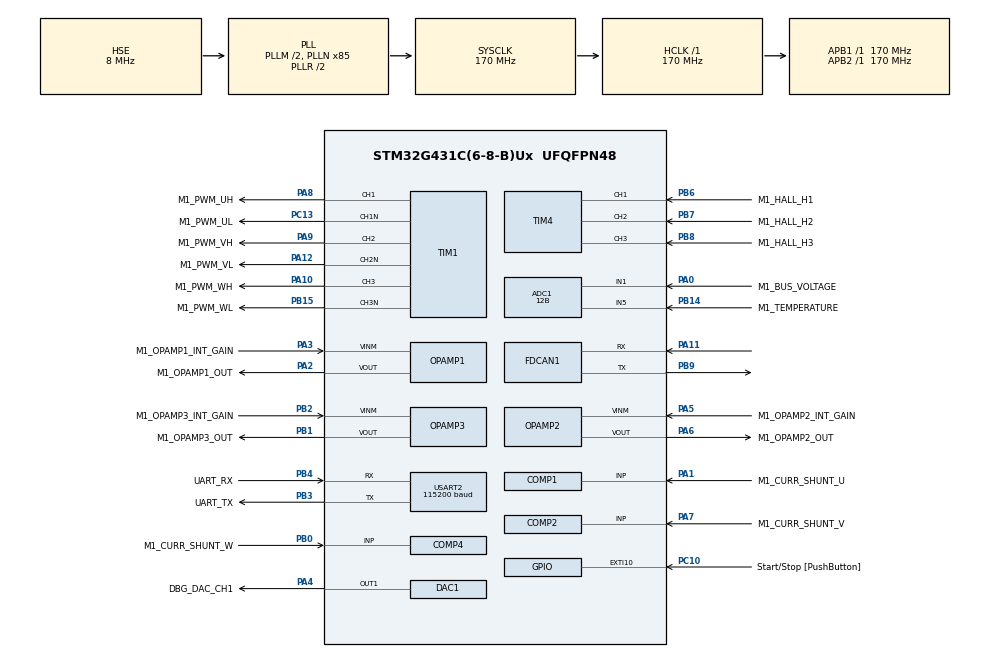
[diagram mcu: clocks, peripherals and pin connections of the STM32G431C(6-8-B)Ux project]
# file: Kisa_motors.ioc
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ADC1.Channel-1\#ChannelRegularConversion=ADC_CHANNEL_1
ADC1.Channel-2\#ChannelRegularConversion=ADC_CHANNEL_5
ADC1.ClockPrescaler=ADC_CLOCK_ASYNC_DIV4
ADC1.ContinuousConvMode=DISABLE
ADC1.DMAContinuousRequests=DISABLE
ADC1.DataAlign=ADC_DATAALIGN_LEFT
ADC1.DiscontinuousConvMode=DISABLE
ADC1.EOCSelection=ADC_EOC_SINGLE_CONV
ADC1.EnableAnalogWatchDog1=false
ADC1.EnableAnalogWatchDog2=false
ADC1.EnableAnalogWatchDog3=false
ADC1.EnableInjectedConversion=ENABLE
ADC1.EnableRegularConversion=ENABLE
ADC1.ExternalTrigConv=ADC_SOFTWARE_START
ADC1.ExternalTrigConvEdge=ADC_EXTERNALTRIGCONVEDGE_NONE
ADC1.ExternalTrigInjecConv=ADC_EXTERNALTRIGINJEC_T1_CC4
ADC1.ExternalTrigInjecConvEdge=ADC_EXTERNALTRIGINJECCONV_EDGE_RISING
ADC1.InjNumberOfConversion=2
ADC1.InjectedChannel-1\#ChannelInjectedConversion=ADC_CHANNEL_3
ADC1.InjectedChannel-2\#ChannelInjectedConversion=ADC_CHANNEL_12
ADC1.InjectedConvMode=None
ADC1.InjectedOffset-1\#ChannelInjectedConversion=0
ADC1.InjectedOffset-2\#ChannelInjectedConversion=0
ADC1.InjectedOffsetNumber-1\#ChannelInjectedConversion=ADC_OFFSET_NONE
ADC1.InjectedOffsetNumber-2\#ChannelInjectedConversion=ADC_OFFSET_NONE
ADC1.InjectedRank-1\#ChannelInjectedConversion=1
ADC1.InjectedRank-2\#ChannelInjectedConversion=2
ADC1.InjectedSamplingTime-1\#ChannelInjectedConversion=ADC_SAMPLETIME_6CYCLES_5
ADC1.InjectedSamplingTime-2\#ChannelInjectedConversion=ADC_SAMPLETIME_6CYCLES_5
ADC1.LowPowerAutoWait=DISABLE
ADC1.NbrOfConversion=2
ADC1.NbrOfConversionFlag=1
ADC1.Offset-1\#ChannelRegularConversion=0
ADC1.Offset-2\#ChannelRegularConversion=0
ADC1.OffsetNumber-1\#ChannelRegularConversion=ADC_OFFSET_NONE
ADC1.OffsetNumber-2\#ChannelRegularConversion=ADC_OFFSET_NONE
ADC1.Overrun=ADC_OVR_DATA_PRESERVED
ADC1.Rank-1\#ChannelRegularConversion=1
ADC1.Rank-2\#ChannelRegularConversion=2
ADC1.Resolution=ADC_RESOLUTION_12B
ADC1.SamplingTime-1\#ChannelRegularConversion=ADC_SAMPLETIME_47CYCLES_5
ADC1.SamplingTime-2\#ChannelRegularConversion=ADC_SAMPLETIME_47CYCLES_5
ADC1.ScanConvMode=ADC_SCAN_ENABLE
ADC1.master=1
ADC2.ClockPrescaler=ADC_CLOCK_ASYNC_DIV4
ADC2.ContinuousConvMode=DISABLE
ADC2.DMAContinuousRequests=DISABLE
ADC2.DataAlign=ADC_DATAALIGN_LEFT
ADC2.DiscontinuousConvMode=DISABLE
ADC2.EOCSelection=ADC_EOC_SINGLE_CONV
ADC2.EnableAnalogWatchDog1=false
ADC2.EnableAnalogWatchDog2=false
ADC2.EnableAnalogWatchDog3=false
ADC2.EnableInjectedConversion=ENABLE
ADC2.EnableRegularConversion=DISABLE
ADC2.ExternalTrigInjecConv=ADC_EXTERNALTRIGINJEC_T1_CC4
ADC2.ExternalTrigInjecConvEdge=ADC_EXTERNALTRIGINJECCONV_EDGE_RISING
ADC2.InjNumberOfConversion=2
ADC2.InjectedChannel-1\#ChannelInjectedConversion=ADC_CHANNEL_3
ADC2.InjectedChannel-2\#ChannelInjectedConversion=ADC_CHANNEL_VOPAMP3_ADC2
ADC2.InjectedConvMode=None
ADC2.InjectedOffset-1\#ChannelInjectedConversion=0
ADC2.InjectedOffset-2\#ChannelInjectedConversion=0
ADC2.InjectedOffsetNumber-1\#ChannelInjectedConversion=ADC_OFFSET_NONE
ADC2.InjectedOffsetNumber-2\#ChannelInjectedConversion=ADC_OFFSET_NONE
ADC2.InjectedRank-1\#ChannelInjectedConversion=1
ADC2.InjectedRank-2\#ChannelInjectedConversion=2
ADC2.InjectedSamplingTime-1\#ChannelInjectedConversion=ADC_SAMPLETIME_6CYCLES_5
ADC2.InjectedSamplingTime-2\#ChannelInjectedConversion=ADC_SAMPLETIME_6CYCLES_5
ADC2.LowPowerAutoWait=DISABLE
ADC2.Overrun=ADC_OVR_DATA_PRESERVED
ADC2.Resolution=ADC_RESOLUTION_12B
ADC2.ScanConvMode=ADC_SCAN_ENABLE
ADC2.master=1
COMP1.Output=COMP_OUTPUT_TIM1BKIN2
COMP2.Output=COMP_OUTPUT_TIM1BKIN2
COMP4.Output=COMP_OUTPUT_TIM1BKIN2
DAC1.DAC_OutputBuffer=DAC_OUTPUTBUFFER_DISABLE
DAC1.DAC_Trigger_OUT1=DAC_TRIGGER_SOFTWARE
ExtraMW=MotorControl
ExtraMW.MotorControl.Config=MotorControl
ExtraMW.MotorControl.Mode=MotorControl
ExtraMW.MotorControl.Root=MCSDK_v5.4.4/MotorControl
ExtraMW.MotorControl.Template=templates
FDCAN1.ClockDivider=FDCAN_CLOCK_DIV10
FDCAN1.DataTimeSeg1=4
FDCAN1.DataTimeSeg2=4
FDCAN1.NominalPrescaler=17
FDCAN1.NominalTimeSeg1=4
FDCAN1.NominalTimeSeg2=4
Mcu.Family=STM32G4
Mcu.Name=STM32G431C(6-8-B)Ux
Mcu.Package=UFQFPN48
MotorControl.ADC_1_PERIPH=ADC1
MotorControl.ADC_2_PERIPH=ADC2
MotorControl.ADC_AHBPERIPH=RCC_AHBPeriph_ADC12
MotorControl.ADC_CLOCK_WB_DIV=4
MotorControl.ADC_CLOCK_WB_FREQ=68
MotorControl.ADC_PERIPH=ADC1
MotorControl.ADC_REFERENCE_VOLTAGE=3.30
MotorControl.ALIGNMENT_ANGLE_DEG=90
MotorControl.ALIGNMENT_DURATION=700
MotorControl.AMPLIFICATION_GAIN=9.14
MotorControl.ANGC={0,0,0,0,0,0,0,0}
MotorControl.BEMF_CONSISTENCY_GAIN=64
MotorControl.BEMF_CONSISTENCY_TOL=64
MotorControl.BKIN1_FILTER=0
MotorControl.BKIN2_FILTER=3
MotorControl.BKIN2_MODE=INT_MODE
MotorControl.BKIN_MODE=NONE
MotorControl.BOARD=B-G431B-ESC1
MotorControl.BRKIN2_GPIO_AF=GPIO_AF_12
MotorControl.BRKIN_GPIO_AF=GPIO_AF_2
MotorControl.BUS_VOLTAGE_READING=true
MotorControl.CCMRAM_ENABLED=false
MotorControl.CLOCK_FREQUENCY=CPU_CLK_170_MHZ
MotorControl.CLOCK_SOURCE=EXTERNAL
MotorControl.CONSTANT1_D=1668126
MotorControl.CONSTANT1_Q=1668126
MotorControl.CONSTANT2_QD=67427
MotorControl.CORD_BEMF_CONSISTENCY_GAIN=64
MotorControl.CORD_BEMF_CONSISTENCY_TOL=64
MotorControl.CORD_F1=16384
MotorControl.CORD_F2=512
MotorControl.CORD_FIFO_DEPTH_01HZ=64
MotorControl.CORD_FIFO_DEPTH_DPP=64
MotorControl.CORD_GAIN1=-24323
MotorControl.CORD_GAIN2=26849
MotorControl.CORD_MAX_ACCEL_DPPP=226
MotorControl.CORD_MEAS_ERRORS_BEFORE_FAULTS=9
MotorControl.CORD_VARIANCE_THRESHOLD=4
MotorControl.CPU_CLK_170_MHZ=true
MotorControl.CTRBDID=10015
MotorControl.CUBE_MX_VER=5.6.0
MotorControl.CURRENT_READING_TOPOLOGY=THREE_SHUNT_INDEPENDENT_RESOURCES
MotorControl.CURR_SAMPLING_TIME=6
MotorControl.DAC_EMULATED=false
MotorControl.DAC_FUNCTIONALITY=true
MotorControl.DAC_TIMER_CH1_GPIO_PIN=LL_GPIO_PIN_4
MotorControl.DAC_TIMER_CH1_GPIO_PORT=GPIOA
MotorControl.DAC_TIMER_CH2_GPIO_PIN=LL_GPIO_PIN_0
MotorControl.DAC_TIMER_CH2_GPIO_PORT=GPIOA
MotorControl.DAC_TIMER_SELECTION=TIM3
MotorControl.DC_CURRENT_RS_MEAS=8.00
MotorControl.DEBUG_DAC_CH1=true
MotorControl.DEBUG_DAC_CH2=false
MotorControl.DEFAULT_CONTROL_MODE=STC_SPEED_MODE
MotorControl.DEFAULT_DAC_CHANNEL_1=MC_PROTOCOL_REG_OBS_EL_ANGLE
MotorControl.DEFAULT_DAC_CHANNEL_2=MC_PROTOCOL_REG_I_B
MotorControl.DEFAULT_DAC_MOTOR=0
MotorControl.DEFAULT_FLUX_COMPONENT=0
MotorControl.DEFAULT_TARGET_SPEED_RPM=1500
MotorControl.DEFAULT_TORQUE_COMPONENT=0
MotorControl.DISSIPATIVE_BRAKE_POLARITY=DOUT_ACTIVE_HIGH
MotorControl.DRIVES_NUMBER_SELECTION=SINGLEDRIVE
MotorControl.EMERGENCY2_STOP_GPIO_PIN=LL_GPIO_PIN_11
MotorControl.EMERGENCY2_STOP_GPIO_PORT=GPIOA
MotorControl.EMERGENCY_STOP_GPIO_PIN=LL_GPIO_PIN_11
MotorControl.EMERGENCY_STOP_GPIO_PORT=GPIOA
MotorControl.ENABLE_SL_ALGO_FROM_PHASE=3
MotorControl.ENCODER_AVAILABLE=false
MotorControl.ENCODER_PPR=400
MotorControl.ENC_AVERAGING_FIFO_DEPTH=16
MotorControl.ENC_A_GPIO_PIN=LL_GPIO_PIN_0
MotorControl.ENC_A_GPIO_PORT=GPIOA
MotorControl.ENC_B_GPIO_PIN=LL_GPIO_PIN_1
MotorControl.ENC_B_GPIO_PORT=GPIOA
MotorControl.ENC_ICx_FILTER=119
MotorControl.ENC_INVERT_SPEED=false
MotorControl.ENC_MEAS_ERRORS_BEFORE_FAULTS=9
MotorControl.ENC_TIMER_REMAPPING=NO_REMAP_TIM2
MotorControl.ENC_TIMER_SELECTION=ENC_TIM2
MotorControl.ENC_USE_CH3=false
MotorControl.EXT_CLK_8_MHZ=true
MotorControl.EXT_CLOCK_FREQUENCY=EXT_CLK_8_MHZ
MotorControl.F1=16384
MotorControl.F2=512
MotorControl.FEEDBACK_NET_FILTERING=true
MotorControl.FEED_FORWARD_CURRENT_REG_ENABLING=false
MotorControl.FINAL_I_ALIGNMENT=1061
MotorControl.FLUX_WEAKENING_ENABLING=false
MotorControl.FW_KIDIV=32768
MotorControl.FW_KI_GAIN=5000
MotorControl.FW_KPDIV=32768
MotorControl.FW_KP_GAIN=3000
MotorControl.FW_VOLTAGE_REF=985
MotorControl.GAIN1=-24323
MotorControl.GAIN2=26849
MotorControl.H1_GPIO_PIN=LL_GPIO_PIN_6
MotorControl.H1_GPIO_PORT=GPIOB
MotorControl.H2_GPIO_PIN=LL_GPIO_PIN_7
MotorControl.H2_GPIO_PORT=GPIOB
MotorControl.H3_GPIO_PIN=LL_GPIO_PIN_8
MotorControl.H3_GPIO_PORT=GPIOB
MotorControl.HALL_AVERAGING_FIFO_DEPTH=1
MotorControl.HALL_ICx_FILTER=48
MotorControl.HALL_MEAS_ERRORS_BEFORE_FAULTS=9
MotorControl.HALL_MTPA=false
MotorControl.HALL_PHASE_SHIFT=120
MotorControl.HALL_SENSORS=true
MotorControl.HALL_SENSORS_AVAILABLE=true
MotorControl.HALL_SENSORS_PLACEMENT=DEGREES_120
MotorControl.HALL_TIMER_REMAPPING=NO_REMAP_TIM4
MotorControl.HALL_TIMER_SELECTION=HALL_TIM4
MotorControl.HFI_AMPLITUDE=25
MotorControl.HFI_DC_0_COEFF=0.00146
MotorControl.HFI_DC_1_COEFF=0.002921
MotorControl.HFI_DC_2_COEFF=0.00146
MotorControl.HFI_DC_3_COEFF=1.889033
MotorControl.HFI_DC_4_COEFF=-0.894874
MotorControl.HFI_DEBUG_MODE=false
MotorControl.HFI_FREQUENCY=400
MotorControl.HFI_HIFRAMPLSCAN=25
MotorControl.HFI_HP_ID_0_COEFF=0.925191
MotorControl.HFI_HP_ID_1_COEFF=-1.850383
MotorControl.HFI_HP_ID_2_COEFF=0.925191
MotorControl.HFI_HP_ID_3_COEFF=1.844778
MotorControl.HFI_HP_ID_4_COEFF=-0.855987
MotorControl.HFI_IDH_DELAY=32400
MotorControl.HFI_LOCKFREQ=41
MotorControl.HFI_LP_ID_0_COEFF=0.009086
MotorControl.HFI_LP_ID_1_COEFF=0.018172
MotorControl.HFI_LP_ID_2_COEFF=0.009086
MotorControl.HFI_LP_ID_3_COEFF=1.712838
MotorControl.HFI_LP_ID_4_COEFF=-0.749181
MotorControl.HFI_MAXANGLEDIFF=3640
MotorControl.HFI_MINIMUM_SPEED_RPM=402
MotorControl.HFI_NOTCH_IQD_0_COEFF=0.962363
MotorControl.HFI_NOTCH_IQD_1_COEFF=-1.90103
MotorControl.HFI_NOTCH_IQD_2_COEFF=0.962363
MotorControl.HFI_NOTCH_IQD_3_COEFF=1.90103
MotorControl.HFI_NOTCH_IQD_4_COEFF=-0.924727
MotorControl.HFI_NSDETPOINTSSKIP=10
MotorControl.HFI_NSMAXDETPOINTS=20
MotorControl.HFI_NS_MIN_SAT_DIFF=0
MotorControl.HFI_PID_KIDIV=32768
MotorControl.HFI_PID_KI_DEFAULT=400
MotorControl.HFI_PID_KPDIV=16384
MotorControl.HFI_PID_KP_DEFAULT=800
MotorControl.HFI_PLL_KI_DEFAULT=0.00400
MotorControl.HFI_PLL_KP_DEFAULT=0.00060
MotorControl.HFI_RESTARTTIMESEC=0.1
MotorControl.HFI_RESTART_RPM_TH=(((HFI_STO_RPM_TH)+(STO_HFI_RPM_TH))/2)
MotorControl.HFI_REVERT_DIRECTION=true
MotorControl.HFI_SCANROTATIONSNO=3
MotorControl.HFI_SPD_BUFFER_DEPTH_01HZ=64
MotorControl.HFI_STEPANGLE=3640
MotorControl.HFI_STO_RPM_TH=OBS_MINIMUM_SPEED_RPM
MotorControl.HFI_WAITAFTERNS2=4
MotorControl.HFI_WAITBEFORESN=6
MotorControl.HFI_WAITSYNCH=20
MotorControl.HFI_WAITTRACK=20
MotorControl.HIGH_SIDE_BRAKE_STATE=false
MotorControl.HIGH_SIDE_IDLE_STATE=false
MotorControl.HW_COMPLEMENTED_LOW_SIDE=false
MotorControl.HW_DEAD_TIME_NS=500
MotorControl.HW_OV_CURRENT_PROT_BYPASS=false
MotorControl.ID_DEMAG=-4356
MotorControl.INRUSH_CURRLIMIT_AT_POWER_ON=true
MotorControl.INRUSH_CURRLIMIT_CHANGE_AFTER_MS=1000
MotorControl.INRUSH_CURRLIMIT_ENABLING=false
MotorControl.INRUSH_CURRLIMIT_GPIO_PIN=LL_GPIO_PIN_4
MotorControl.INRUSH_CURRLIMIT_GPIO_PORT=GPIOD
MotorControl.INRUSH_CURR_LIMITER_POLARITY=DOUT_ACTIVE_HIGH
MotorControl.INTERNAL_OVERCURRENTPROTECTION=true
MotorControl.INTERNAL_OVERVOLTAGEPROTECTION=false
MotorControl.INVERTERBOARD=ESC_G4
MotorControl.IPs=NVIC,RCC,SYS,CORDIC,MotorControl,TIM1,COMP1,COMP2,COMP4,OPAMP1,OPAMP2,OPAMP3,ADC1,ADC2,TIM4,DAC1,USART2
MotorControl.IQMAX=4356
MotorControl.LCD_JOYSTICK_FUNCTIONALITY=false
MotorControl.LCD_MODE=LCD_FULL
MotorControl.LDLQ_RATIO=1.000
MotorControl.LOW_SIDE_BRAKE_STATE=false
MotorControl.LOW_SIDE_IDLE_STATE=false
MotorControl.LOW_SIDE_SIGNALS_ENABLING=LS_PWM_TIMER
MotorControl.LS=0.000577
MotorControl.MAX_APPLICATION_SPEED=300
MotorControl.MAX_MODULATION_99_PER_CENT=true
MotorControl.MAX_MODULATION_INDEX=MAX_MODULATION_99_PER_CENT
MotorControl.MCU=STM32G431CB
MotorControl.MCU_TYPE=STM32G431CB
MotorControl.MC_WORKBENCH_VERSION=5.4.4.20160
MotorControl.MEAS_ERRORS_BEFORE_FAULTS=9
MotorControl.MIN_APPLICATION_SPEED=0
MotorControl.MOTOR_MAX_SPEED_RPM=300
MotorControl.MOTOR_TYPE=PMSM
MotorControl.MOTOR_VOLTAGE_CONSTANT=21.6
MotorControl.MTPA_ENABLING=false
MotorControl.NB_CONSECUTIVE_TESTS=2
MotorControl.NOMINAL_BUS_VOLTAGE_V=12
MotorControl.NOMINAL_CURRENT=4356
MotorControl.OBS_MEAS_ERRORS_BEFORE_FAULTS=9
MotorControl.OBS_MINIMUM_SPEED_RPM=580
MotorControl.OCPA_INVERTINGINPUT=COMPX_InvertingInput_VREF_1_4
MotorControl.OCPA_INVERTINGINPUT_GPIO_PIN=LL_GPIO_PIN_4
MotorControl.OCPA_INVERTINGINPUT_GPIO_PORT=GPIOA
MotorControl.OCPA_INVERTINGINPUT_MODE=INT_MODE
MotorControl.OCPA_NONINVERTINGINPUT=COMP1_NonInvertingInput_PA1
MotorControl.OCPA_NONINVERTINGINPUT_GPIO_PIN=LL_GPIO_PIN_1
MotorControl.OCPA_NONINVERTINGINPUT_GPIO_PORT=GPIOA
MotorControl.OCPA_OUTPUT=COMP_Output_TIM1BKIN2
MotorControl.OCPA_OUTPUTPOL=COMP_OutputPol_NonInverted
MotorControl.OCPA_OUTPUT_GPIO_AF=GPIO_AF_2
MotorControl.OCPA_OUTPUT_GPIO_PIN=LL_GPIO_PIN_0
MotorControl.OCPA_OUTPUT_GPIO_PORT=GPIOA
MotorControl.OCPA_OUTPUT_MODE=INT_MODE
MotorControl.OCPA_SELECTION=COMP1
MotorControl.OCPB_INVERTINGINPUT=COMPX_InvertingInput_VREF_1_4
MotorControl.OCPB_INVERTINGINPUT_GPIO_PIN=LL_GPIO_PIN_4
MotorControl.OCPB_INVERTINGINPUT_GPIO_PORT=GPIOA
MotorControl.OCPB_INVERTINGINPUT_MODE=INT_MODE
MotorControl.OCPB_NONINVERTINGINPUT=COMP2_NonInvertingInput_PA7
MotorControl.OCPB_NONINVERTINGINPUT_GPIO_PIN=LL_GPIO_PIN_7
MotorControl.OCPB_NONINVERTINGINPUT_GPIO_PORT=GPIOA
MotorControl.OCPB_OUTPUT=COMP_Output_TIM1BKIN2
MotorControl.OCPB_OUTPUTPOL=COMP_OutputPol_NonInverted
MotorControl.OCPB_OUTPUT_GPIO_AF=GPIO_AF_2
MotorControl.OCPB_OUTPUT_GPIO_PIN=LL_GPIO_PIN_2
MotorControl.OCPB_OUTPUT_GPIO_PORT=GPIOA
MotorControl.OCPB_OUTPUT_MODE=INT_MODE
MotorControl.OCPB_SELECTION=COMP2
MotorControl.OCPC_INVERTINGINPUT=COMPX_InvertingInput_VREF_1_4
MotorControl.OCPC_INVERTINGINPUT_GPIO_PIN=LL_GPIO_PIN_4
MotorControl.OCPC_INVERTINGINPUT_GPIO_PORT=GPIOA
MotorControl.OCPC_INVERTINGINPUT_MODE=INT_MODE
MotorControl.OCPC_NONINVERTINGINPUT=COMP4_NonInvertingInput_PB0
MotorControl.OCPC_NONINVERTINGINPUT_GPIO_PIN=LL_GPIO_PIN_0
MotorControl.OCPC_NONINVERTINGINPUT_GPIO_PORT=GPIOB
MotorControl.OCPC_OUTPUT=COMP_Output_TIM1BKIN2
MotorControl.OCPC_OUTPUTPOL=COMP_OutputPol_NonInverted
MotorControl.OCPC_OUTPUT_GPIO_AF=GPIO_AF_2
MotorControl.OCPC_OUTPUT_GPIO_PIN=LL_GPIO_PIN_1
MotorControl.OCPC_OUTPUT_GPIO_PORT=GPIOB
MotorControl.OCPC_OUTPUT_MODE=INT_MODE
MotorControl.OCPC_SELECTION=COMP4
MotorControl.OCPREF=5957
MotorControl.OCP_COMP_THRESHOLD=0.50
MotorControl.OCP_FILTER=COMP_Mode_HighSpeed
MotorControl.OCP_INVERTINGINPUT=COMPX_InvertingInput_VREF_1_4
MotorControl.OCP_INVERTINGINPUT_GPIO_PIN=LL_GPIO_PIN_4
MotorControl.OCP_INVERTINGINPUT_GPIO_PORT=GPIOA
MotorControl.OCP_INVERTINGINPUT_MODE=INT_MODE
MotorControl.OCP_NONINVERTINGINPUT=COMP2_NonInvertingInput_PA7
MotorControl.OCP_NONINVERTINGINPUT_GPIO_PIN=LL_GPIO_PIN_7
MotorControl.OCP_NONINVERTINGINPUT_GPIO_PORT=GPIOA
MotorControl.OCP_OUTPUT=COMP_Output_TIM1BKIN2
MotorControl.OCP_OUTPUTPOL=COMP_OutputPol_NonInverted
MotorControl.OCP_OUTPUT_GPIO_AF=GPIO_AF_2
MotorControl.OCP_OUTPUT_GPIO_PIN=LL_GPIO_PIN_2
MotorControl.OCP_OUTPUT_GPIO_PORT=GPIOA
MotorControl.OCP_OUTPUT_MODE=INT_MODE
MotorControl.OCP_SELECTION=COMP2
MotorControl.OFST={0,0,0,0,0,0,0,0}
MotorControl.ON_OVER_VOLTAGE=TURN_OFF_PWM
MotorControl.OPAMP1_INVERTINGINPUT=OPAMP1_InvertingInput_PA3
MotorControl.OPAMP1_INVERTINGINPUT_GPIO_PIN=LL_GPIO_PIN_3
MotorControl.OPAMP1_INVERTINGINPUT_GPIO_PORT=GPIOA
MotorControl.OPAMP1_INVERTINGINPUT_MODE=EXT_MODE
MotorControl.OPAMP1_NONINVERTINGINPUT_PHA=OPAMP1_NonInvertingInput_PA1
MotorControl.OPAMP1_NONINVERTINGINPUT_PHA_GPIO_PIN=LL_GPIO_PIN_1
MotorControl.OPAMP1_NONINVERTINGINPUT_PHA_GPIO_PORT=GPIOA
MotorControl.OPAMP1_NONINVERTINGINPUT_PHB=OPAMP1_NonInvertingInput_PA1
MotorControl.OPAMP1_NONINVERTINGINPUT_PHB_GPIO_PIN=LL_GPIO_PIN_1
MotorControl.OPAMP1_NONINVERTINGINPUT_PHB_GPIO_PORT=GPIOA
MotorControl.OPAMP1_OUT_GPIO_PIN=LL_GPIO_PIN_2
MotorControl.OPAMP1_OUT_GPIO_PORT=GPIOA
MotorControl.OPAMP1_SELECTION=OPAMP1
MotorControl.OPAMP2_INVERTINGINPUT=OPAMP2_InvertingInput_PA5
MotorControl.OPAMP2_INVERTINGINPUT_GPIO_PIN=LL_GPIO_PIN_5
MotorControl.OPAMP2_INVERTINGINPUT_GPIO_PORT=GPIOA
MotorControl.OPAMP2_INVERTINGINPUT_MODE=EXT_MODE
MotorControl.OPAMP2_NONINVERTINGINPUT_PHA=OPAMP2_NonInvertingInput_PA7
MotorControl.OPAMP2_NONINVERTINGINPUT_PHA_GPIO_PIN=LL_GPIO_PIN_7
MotorControl.OPAMP2_NONINVERTINGINPUT_PHA_GPIO_PORT=GPIOA
MotorControl.OPAMP2_NONINVERTINGINPUT_PHB=OPAMP2_NonInvertingInput_PA7
MotorControl.OPAMP2_NONINVERTINGINPUT_PHB_GPIO_PIN=LL_GPIO_PIN_7
MotorControl.OPAMP2_NONINVERTINGINPUT_PHB_GPIO_PORT=GPIOA
MotorControl.OPAMP2_NONINVERTINGINPUT_PHC=OPAMP2_NonInvertingInput_PA7
MotorControl.OPAMP2_NONINVERTINGINPUT_PHC_GPIO_PIN=LL_GPIO_PIN_7
MotorControl.OPAMP2_NONINVERTINGINPUT_PHC_GPIO_PORT=GPIOA
MotorControl.OPAMP2_OUT_GPIO_PIN=LL_GPIO_PIN_6
MotorControl.OPAMP2_OUT_GPIO_PORT=GPIOA
MotorControl.OPAMP2_SELECTION=OPAMP2
MotorControl.OPAMP3_INVERTINGINPUT=OPAMP3_InvertingInput_PB2
MotorControl.OPAMP3_INVERTINGINPUT_GPIO_PIN=LL_GPIO_PIN_2
MotorControl.OPAMP3_INVERTINGINPUT_GPIO_PORT=GPIOB
MotorControl.OPAMP3_INVERTINGINPUT_MODE=EXT_MODE
MotorControl.OPAMP3_NONINVERTINGINPUT_PHA=OPAMP3_NonInvertingInput_PB0
MotorControl.OPAMP3_NONINVERTINGINPUT_PHA_GPIO_PIN=LL_GPIO_PIN_0
MotorControl.OPAMP3_NONINVERTINGINPUT_PHA_GPIO_PORT=GPIOB
MotorControl.OPAMP3_NONINVERTINGINPUT_PHB=OPAMP3_NonInvertingInput_PB0
MotorControl.OPAMP3_NONINVERTINGINPUT_PHB_GPIO_PIN=LL_GPIO_PIN_0
MotorControl.OPAMP3_NONINVERTINGINPUT_PHB_GPIO_PORT=GPIOB
MotorControl.OPAMP3_NONINVERTINGINPUT_PHC=OPAMP3_NonInvertingInput_PB0
MotorControl.OPAMP3_NONINVERTINGINPUT_PHC_GPIO_PIN=LL_GPIO_PIN_0
MotorControl.OPAMP3_NONINVERTINGINPUT_PHC_GPIO_PORT=GPIOB
MotorControl.OPAMP3_OUT_GPIO_PIN=LL_GPIO_PIN_1
MotorControl.OPAMP3_OUT_GPIO_PORT=GPIOB
MotorControl.OPAMP3_SELECTION=OPAMP3
MotorControl.OPAMP_INVERTINGINPUT=OPAMP1_InvertingInput_PA3
MotorControl.OPAMP_INVERTINGINPUT_GPIO_PIN=LL_GPIO_PIN_3
MotorControl.OPAMP_INVERTINGINPUT_GPIO_PORT=GPIOA
MotorControl.OPAMP_INVERTINGINPUT_MODE=EXT_MODE
MotorControl.OPAMP_NONINVERTINGINPUT=OPAMP1_NonInvertingInput_PA7
MotorControl.OPAMP_NONINVERTINGINPUT_GPIO_PIN=LL_GPIO_PIN_7
MotorControl.OPAMP_NONINVERTINGINPUT_GPIO_PORT=GPIOA
MotorControl.OPAMP_OUT_GPIO_PIN=LL_GPIO_PIN_2
MotorControl.OPAMP_OUT_GPIO_PORT=GPIOA
MotorControl.OPAMP_PGACONNECT=OPAMP1_PGAConnect_PA3
MotorControl.OPAMP_PGAGAIN=OPAMP_OPAMP_PGAGain_16
MotorControl.OPAMP_SELECTION=OPAMP1
MotorControl.OPAMP_TYPE_GAIN=INTERNAL
MotorControl.OPEN_LOOP_FOC=false
MotorControl.OPEN_LOOP_K=44
MotorControl.OPEN_LOOP_OFF=4400
MotorControl.OPEN_LOOP_SPEED_RAMP_DURATION_MS=1000
MotorControl.OPEN_LOOP_SPEED_RPM=100
MotorControl.OPEN_LOOP_VF=false
MotorControl.OPEN_LOOP_VOLTAGE_d=6000
MotorControl.OVERCURR_FEEDBACK_POLARITY=EMSTOP_ACTIVE_LOW
MotorControl.OVERCURR_PROTECTION_HW_DISABLING=DOUT_ACTIVE_HIGH
MotorControl.OVPREF=23830
MotorControl.OVP_FILTER=COMP_Mode_HighSpeed
MotorControl.OVP_INVERTINGINPUT=COMPX_InvertingInput_VREF
MotorControl.OVP_INVERTINGINPUT_GPIO_PIN=LL_GPIO_PIN_4
MotorControl.OVP_INVERTINGINPUT_GPIO_PORT=GPIOA
MotorControl.OVP_INVERTINGINPUT_MODE=INT_MODE
MotorControl.OVP_NONINVERTINGINPUT=COMP2_NonInvertingInput_PA7
MotorControl.OVP_NONINVERTINGINPUT_GPIO_PIN=LL_GPIO_PIN_7
MotorControl.OVP_NONINVERTINGINPUT_GPIO_PORT=GPIOA
MotorControl.OVP_OUTPUT=COMP_Output_TIM1BKIN
MotorControl.OVP_OUTPUTPOL=COMP_OutputPol_NonInverted
MotorControl.OVP_OUTPUT_GPIO_AF=GPIO_AF_2
MotorControl.OVP_OUTPUT_GPIO_PIN=LL_GPIO_PIN_2
MotorControl.OVP_OUTPUT_GPIO_PORT=GPIOA
MotorControl.OVP_OUTPUT_MODE=INT_MODE
MotorControl.OVP_SELECTION=COMP2
MotorControl.OV_CURR_BYPASS_GPIO_PIN=LL_GPIO_PIN_5
MotorControl.OV_CURR_BYPASS_GPIO_PORT=GPIOD
MotorControl.OV_TEMPERATURE_HYSTERESIS_C=10
MotorControl.OV_TEMPERATURE_PROT_ENABLING=true
MotorControl.OV_TEMPERATURE_THRESHOLD_C=110
MotorControl.OV_VOLTAGE_PROT_ENABLING=true
MotorControl.OV_VOLTAGE_THRESHOLD_V=28
MotorControl.PHASE1_DURATION=0
MotorControl.PHASE1_FINAL_CURRENT=0
MotorControl.PHASE1_FINAL_SPEED_RPM=0
MotorControl.PHASE2_DURATION=700
MotorControl.PHASE2_FINAL_CURRENT=326
MotorControl.PHASE2_FINAL_SPEED_RPM=0
MotorControl.PHASE3_DURATION=350
MotorControl.PHASE3_FINAL_CURRENT=381
MotorControl.PHASE3_FINAL_SPEED_RPM=630
MotorControl.PHASE4_DURATION=1150
MotorControl.PHASE4_FINAL_CURRENT=381
MotorControl.PHASE4_FINAL_SPEED_RPM=2700
MotorControl.PHASE5_DURATION=0
MotorControl.PHASE5_FINAL_CURRENT=381
MotorControl.PHASE5_FINAL_SPEED_RPM=2700
MotorControl.PHASE_CURRENTS_ADC=ADC1_2
MotorControl.PHASE_CURRENTS_CHANNEL=ADC_CHANNEL_9
MotorControl.PHASE_CURRENTS_GPIO_PIN=LL_GPIO_PIN_0
MotorControl.PHASE_CURRENTS_GPIO_PORT=GPIOA
MotorControl.PHASE_UH_GPIO_AF=GPIO_AF_6
MotorControl.PHASE_UH_GPIO_PIN=LL_GPIO_PIN_8
MotorControl.PHASE_UH_GPIO_PORT=GPIOA
MotorControl.PHASE_UH_POLARITY=H_ACTIVE_HIGH
MotorControl.PHASE_UL_GPIO_AF=GPIO_AF_4
MotorControl.PHASE_UL_GPIO_PIN=LL_GPIO_PIN_13
MotorControl.PHASE_UL_GPIO_PORT=GPIOC
MotorControl.PHASE_UL_POLARITY=L_ACTIVE_HIGH
MotorControl.PHASE_U_CURR_ADC=ADC1
MotorControl.PHASE_U_CURR_CHANNEL=ADC_CHANNEL_3
MotorControl.PHASE_U_GPIO_PIN=LL_GPIO_PIN_2
MotorControl.PHASE_U_GPIO_PORT=GPIOA
MotorControl.PHASE_VH_GPIO_AF=GPIO_AF_6
MotorControl.PHASE_VH_GPIO_PIN=LL_GPIO_PIN_9
MotorControl.PHASE_VH_GPIO_PORT=GPIOA
MotorControl.PHASE_VH_POLARITY=H_ACTIVE_HIGH
MotorControl.PHASE_VL_GPIO_AF=GPIO_AF_2
MotorControl.PHASE_VL_GPIO_PIN=LL_GPIO_PIN_12
MotorControl.PHASE_VL_GPIO_PORT=GPIOA
MotorControl.PHASE_VL_POLARITY=L_ACTIVE_HIGH
MotorControl.PHASE_V_CURR_ADC=ADC2
MotorControl.PHASE_V_CURR_CHANNEL=ADC_CHANNEL_3
MotorControl.PHASE_V_GPIO_PIN=LL_GPIO_PIN_6
MotorControl.PHASE_V_GPIO_PORT=GPIOA
MotorControl.PHASE_WH_GPIO_AF=GPIO_AF_6
MotorControl.PHASE_WH_GPIO_PIN=LL_GPIO_PIN_10
MotorControl.PHASE_WH_GPIO_PORT=GPIOA
MotorControl.PHASE_WH_POLARITY=H_ACTIVE_HIGH
MotorControl.PHASE_WL_GPIO_AF=GPIO_AF_4
MotorControl.PHASE_WL_GPIO_PIN=LL_GPIO_PIN_15
MotorControl.PHASE_WL_GPIO_PORT=GPIOB
MotorControl.PHASE_WL_POLARITY=L_ACTIVE_HIGH
MotorControl.PHASE_W_CURR_ADC=ADC1
MotorControl.PHASE_W_CURR_CHANNEL=ADC_CHANNEL_12
MotorControl.PHASE_W_GPIO_PIN=LL_GPIO_PIN_1
MotorControl.PHASE_W_GPIO_PORT=GPIOB
MotorControl.PID_FLUX_KD_DEFAULT=100
MotorControl.PID_FLUX_KI_DEFAULT=3903
MotorControl.PID_FLUX_KP_DEFAULT=2963
MotorControl.PID_SPEED_KD_DEFAULT=0
MotorControl.PID_SPEED_KI_DEFAULT=700
MotorControl.PID_SPEED_KP_DEFAULT=1000
MotorControl.PID_TORQUE_KD_DEFAULT=100
MotorControl.PID_TORQUE_KI_DEFAULT=3903
MotorControl.PID_TORQUE_KP_DEFAULT=2963
MotorControl.PLL_KI_GAIN=6
MotorControl.PLL_KP_GAIN=150
MotorControl.POLE_PAIR_NUM=15
MotorControl.POSITION_CTRL_ENABLING=false
MotorControl.PWBDID=10015
MotorControl.PWM_FREQUENCY=16000
MotorControl.PWM_TIMER_REMAPPING=PWM_PARTIAL_REMAP
MotorControl.PWM_TIMER_SELECTION=PWM_TIM1
MotorControl.REGCONVADC=ADC1
MotorControl.REGULATION_EXECUTION_RATE=1
MotorControl.RS=0.19
MotorControl.RSHUNT=0.00300
MotorControl.RTOS=NONE
MotorControl.R_BRAKE_GPIO_PIN=LL_GPIO_PIN_5
MotorControl.R_BRAKE_GPIO_PORT=GPIOD
MotorControl.R_BRAKE_SWITCH_OFF_THRES_V=22
MotorControl.SEGDIV=0
MotorControl.SERIAL_COMMUNICATION=true
MotorControl.SERIAL_COM_CHANNEL1=MC_PROTOCOL_REG_I_A
MotorControl.SERIAL_COM_CHANNEL2=MC_PROTOCOL_REG_I_A
MotorControl.SERIAL_COM_MODE=COM_BIDIRECTIONAL
MotorControl.SERIAL_COM_MOTOR=0
MotorControl.SHARED_SIGNAL_ENABLE=false
MotorControl.SINGLEDRIVE=true
MotorControl.SPD_DIFFERENTIAL_TERM_ENABLING=false
MotorControl.SPEED_BAND_LOWER_LIMIT=15
MotorControl.SPEED_BAND_UPPER_LIMIT=17
MotorControl.SPEED_LOOP_FREQUENCY_HZ=2000
MotorControl.SPEED_SENSOR_SELECTION=HALL_SENSORS
MotorControl.SP_KDDIV=16
MotorControl.SP_KIDIV=256
MotorControl.SP_KPDIV=16
MotorControl.STARTING_ANGLE_DEG=90
MotorControl.START_STOP_BTN=true
MotorControl.START_STOP_GPIO_PIN=LL_GPIO_PIN_10
MotorControl.START_STOP_GPIO_PORT=GPIOC
MotorControl.START_STOP_POLARITY=DIN_ACTIVE_LOW
MotorControl.START_STOP_POLARITY_EDGE=GPIO_NOPULL
MotorControl.STM32G431CB=true
MotorControl.STO_FIFO_DEPTH_01HZ=64
MotorControl.STO_FIFO_DEPTH_DPP=64
MotorControl.STO_HFI_RPM_TH=460
MotorControl.SW_DEADTIME_NS=800
MotorControl.SW_OV_CURRENT_PROT_ENABLING=true
MotorControl.T0_C=25
MotorControl.TEMPERATURE_READING=true
MotorControl.TEMP_ADC_SAMPLING_TIME=47
MotorControl.TEMP_FDBK_ADC=ADC1
MotorControl.TEMP_FDBK_CHANNEL=ADC_CHANNEL_5
MotorControl.TEMP_FDBK_GPIO_PIN=LL_GPIO_PIN_14
MotorControl.TEMP_FDBK_GPIO_PORT=GPIOB
MotorControl.TFDIFFERENTIAL_TERM_ENABLING=false
MotorControl.TF_KDDIV=8192
MotorControl.TF_KIDIV=16384
MotorControl.TF_KPDIV=256
MotorControl.THREE_SHUNT_INDEPENDENT_RESOURCES=true
MotorControl.TNOISE_NS=1000
MotorControl.TRANSITION_DURATION=25
MotorControl.TRISE_NS=2000
MotorControl.T_MAX=110
MotorControl.UD_VOLTAGE_THRESHOLD_V=8
MotorControl.USART_REMAPPING=NO_REMAP_USART2
MotorControl.USART_RX_GPIO_PIN=LL_GPIO_PIN_4
MotorControl.USART_RX_GPIO_PORT=GPIOB
MotorControl.USART_SELECTION=USE_USART2
MotorControl.USART_SPEED=115200
MotorControl.USART_TX_GPIO_PIN=LL_GPIO_PIN_3
MotorControl.USART_TX_GPIO_PORT=GPIOB
MotorControl.USE_3OPAMPS=true
MotorControl.USE_INTERNAL_OPAMP=true
MotorControl.UV_VOLTAGE_PROT_ENABLING=true
MotorControl.V0_V=1.055
MotorControl.VARIANCE_THRESHOLD=0.1
MotorControl.VBUS_ADC=ADC1
MotorControl.VBUS_ADC_SAMPLING_TIME=47
MotorControl.VBUS_CHANNEL=ADC_CHANNEL_1
MotorControl.VBUS_GPIO_PIN=LL_GPIO_PIN_0
MotorControl.VBUS_GPIO_PORT=GPIOA
MotorControl.VBUS_PARTITIONING_FACTOR=0.0963
MotorControl.WB_to_Mx_template_version=20-04-17
MotorControl.WB_to_Mx_version=1.1.0
MotorControl.dV_dT=0.023
NVIC.ADC1_2_IRQn=true\:2\:0\:true\:true\:false\:3\:true\:true
NVIC.EXTI15_10_IRQn=true\:3\:0\:false\:true\:false\:6\:true\:true
NVIC.FDCAN1_IT0_IRQn=true\:0\:0\:false\:false\:true\:true\:true
NVIC.PriorityGroup=NVIC_PRIORITYGROUP_3
NVIC.TIM1_BRK_TIM15_IRQn=true\:4\:1\:true\:true\:false\:1\:true\:true
NVIC.TIM1_UP_TIM16_IRQn=true\:0\:0\:false\:true\:false\:2\:true\:true
NVIC.TIM4_IRQn=true\:3\:0\:false\:true\:false\:4\:true\:true
NVIC.USART2_IRQn=true\:3\:1\:true\:true\:false\:5\:true\:true
OPAMP1.PgaGain=OPAMP_PGA_GAIN_16_OR_MINUS_15
OPAMP1.SelfCalibration=Disable
OPAMP2.PgaGain=OPAMP_PGA_GAIN_16_OR_MINUS_15
OPAMP2.SelfCalibration=Disable
OPAMP3.PgaGain=OPAMP_PGA_GAIN_16_OR_MINUS_15
OPAMP3.SelfCalibration=Disable
PA0.GPIO_Label=M1_BUS_VOLTAGE
PA0.Mode=IN1-Single-Ended
PA0.Signal=ADC1_IN1
PA1.GPIO_Label=M1_CURR_SHUNT_U
PA1.Signal=SharedAnalog_PA1
PA10.GPIO_Label=M1_PWM_WH
PA10.GPIO_PuPd=GPIO_PULLDOWN
PA10.GPIO_Speed=GPIO_SPEED_FREQ_HIGH
PA10.Signal=S_TIM1_CH3
PA11.Mode=FDCANMaster
PA11.Signal=FDCAN1_RX
PA12.GPIO_Label=M1_PWM_VL
PA12.GPIO_PuPd=GPIO_PULLDOWN
PA12.GPIO_Speed=GPIO_SPEED_FREQ_HIGH
PA12.Mode=PWM Generation2 CH2 CH2N
PA12.Signal=TIM1_CH2N
PA13.GPIO_Label=TMS
PA13.Mode=Serial_Wire
PA13.Signal=SYS_JTMS-SWDIO
PA14.GPIO_Label=TCK
PA14.Mode=Serial_Wire
PA14.Signal=SYS_JTCK-SWCLK
PA2.GPIO_Label=M1_OPAMP1_OUT
PA2.Signal=SharedAnalog_PA2
PA3.GPIO_Label=M1_OPAMP1_INT_GAIN
PA3.Mode=PGA Connected-INVERTINGINPUT_IO0_BIAS
PA3.Signal=OPAMP1_VINM
PA4.GPIO_Label=DBG_DAC_CH1
PA4.Signal=COMP_DAC11_group
PA5.GPIO_Label=M1_OPAMP2_INT_GAIN
PA5.Mode=PGA Connected-INVERTINGINPUT_IO0_BIAS
PA5.Signal=OPAMP2_VINM
PA6.GPIO_Label=M1_OPAMP2_OUT
PA6.Signal=SharedAnalog_PA6
PA7.GPIO_Label=M1_CURR_SHUNT_V
PA7.Signal=SharedAnalog_PA7
PA8.GPIO_Label=M1_PWM_UH
PA8.GPIO_PuPd=GPIO_PULLDOWN
PA8.GPIO_Speed=GPIO_SPEED_FREQ_HIGH
PA8.Signal=S_TIM1_CH1
PA9.GPIO_Label=M1_PWM_VH
PA9.GPIO_PuPd=GPIO_PULLDOWN
PA9.GPIO_Speed=GPIO_SPEED_FREQ_HIGH
PA9.Signal=S_TIM1_CH2
PB0.GPIO_Label=M1_CURR_SHUNT_W
PB0.Signal=SharedAnalog_PB0
PB1.GPIO_Label=M1_OPAMP3_OUT
PB1.Signal=SharedAnalog_PB1
PB14.GPIO_Label=M1_TEMPERATURE
PB14.Mode=IN5-Single-Ended
PB14.Signal=ADC1_IN5
PB15.GPIO_Label=M1_PWM_WL
PB15.GPIO_PuPd=GPIO_PULLDOWN
PB15.GPIO_Speed=GPIO_SPEED_FREQ_HIGH
PB15.Mode=PWM Generation3 CH3 CH3N
PB15.Signal=TIM1_CH3N
PB2.GPIO_Label=M1_OPAMP3_INT_GAIN
PB2.Mode=PGA Connected-INVERTINGINPUT_IO0_BIAS
PB2.Signal=OPAMP3_VINM
PB3.GPIO_Label=UART_TX
PB3.GPIO_Mode=GPIO_MODE_AF_PP
PB3.GPIO_PuPd=GPIO_NOPULL
PB3.GPIO_Speed=GPIO_SPEED_FREQ_LOW
PB3.Mode=Asynchronous
PB3.Signal=USART2_TX
PB4.GPIO_Label=UART_RX
PB4.GPIO_Mode=GPIO_MODE_AF_PP
PB4.GPIO_PuPd=GPIO_NOPULL
PB4.GPIO_Speed=GPIO_SPEED_FREQ_LOW
PB4.Mode=Asynchronous
PB4.Signal=USART2_RX
PB6.GPIO_Label=M1_HALL_H1
PB6.GPIO_Speed=GPIO_SPEED_FREQ_HIGH
PB6.Signal=S_TIM4_CH1
PB7.GPIO_Label=M1_HALL_H2
PB7.GPIO_Speed=GPIO_SPEED_FREQ_HIGH
PB7.Signal=S_TIM4_CH2
PB8-BOOT0.GPIO_Label=M1_HALL_H3
PB8-BOOT0.GPIO_Speed=GPIO_SPEED_FREQ_HIGH
PB8-BOOT0.Signal=S_TIM4_CH3
PB9.Mode=FDCANMaster
PB9.Signal=FDCAN1_TX
PC10.GPIO_Label=Start/Stop [PushButton]
PC10.GPIO_ModeDefaultEXTI=GPIO_MODE_IT_FALLING
PC10.GPIO_PuPd=GPIO_NOPULL
PC10.Signal=GPXTI10
PC13.GPIO_Label=M1_PWM_UL
PC13.GPIO_PuPd=GPIO_PULLDOWN
PC13.GPIO_Speed=GPIO_SPEED_FREQ_HIGH
PC13.Mode=PWM Generation1 CH1 CH1N
PC13.Signal=TIM1_CH1N
PF0-OSC_IN.Mode=HSE-External-Oscillator
PF0-OSC_IN.Signal=RCC_OSC_IN
PF1-OSC_OUT.Mode=HSE-External-Oscillator
PF1-OSC_OUT.Signal=RCC_OSC_OUT
ProjectManager.HeapSize=0x200
ProjectManager.StackSize=0x400
ProjectManager.TargetToolchain=SW4STM32
RCC.ADC12CLockSelection=RCC_ADC12CLKSOURCE_PLL
RCC.ADC12Freq_Value=42500000
RCC.AHBFreq_Value=170000000
RCC.APB1Freq_Value=170000000
RCC.APB1TimFreq_Value=170000000
RCC.APB2Freq_Value=170000000
RCC.APB2TimFreq_Value=170000000
RCC.CortexFreq_Value=170000000
RCC.EXTERNAL_CLOCK_VALUE=12288000
RCC.HCLKFreq_Value=170000000
RCC.HSE_VALUE=8000000
RCC.HSI48_VALUE=48000000
RCC.HSI_VALUE=16000000
RCC.LSE_VALUE=32768
RCC.PLLM=RCC_PLLM_DIV2
RCC.PLLN=85
RCC.PLLP=RCC_PLLP_DIV8
RCC.PLLSourceVirtual=RCC_PLLSOURCE_HSE
RCC.SYSCLKFreq_VALUE=170000000
RCC.SYSCLKSource=RCC_SYSCLKSOURCE_PLLCLK
RCC.USBFreq_Value=170000000
RCC.VCOOutputFreq_Value=340000000
SH.COMP_DAC11_group.0=DAC1_OUT1,DAC_OUT1
SH.S_TIM1_CH1.0=TIM1_CH1,PWM Generation1 CH1 CH1N
SH.S_TIM1_CH2.0=TIM1_CH2,PWM Generation2 CH2 CH2N
SH.S_TIM1_CH3.0=TIM1_CH3,PWM Generation3 CH3 CH3N
SH.S_TIM4_CH1.0=TIM4_CH1,Xored_Inputs_Hall_Sensor_Interface
SH.S_TIM4_CH2.0=TIM4_CH2,Xored_Inputs_Hall_Sensor_Interface
SH.S_TIM4_CH3.0=TIM4_CH3,Xored_Inputs_Hall_Sensor_Interface
SH.SharedAnalog_PA1.0=COMP1_INP,INP
SH.SharedAnalog_PA1.1=OPAMP1_VINP,PGA Connected-INVERTINGINPUT_IO0_BIAS
SH.SharedAnalog_PA2.0=OPAMP1_VOUT,PGA Connected-INVERTINGINPUT_IO0_BIAS
SH.SharedAnalog_PA2.1=ADC1_IN3,IN3-Single-Ended
SH.SharedAnalog_PA6.0=OPAMP2_VOUT,PGA Connected-INVERTINGINPUT_IO0_BIAS
SH.SharedAnalog_PA6.1=ADC2_IN3,IN3-Single-Ended
SH.SharedAnalog_PA7.0=COMP2_INP,INP
SH.SharedAnalog_PA7.1=OPAMP2_VINP,PGA Connected-INVERTINGINPUT_IO0_BIAS
SH.SharedAnalog_PB0.0=COMP4_INP,INP
SH.SharedAnalog_PB0.1=OPAMP3_VINP,PGA Connected-INVERTINGINPUT_IO0_BIAS
SH.SharedAnalog_PB1.0=OPAMP3_VOUT,PGA Connected-INVERTINGINPUT_IO0_BIAS
SH.SharedAnalog_PB1.1=ADC1_IN12,IN12-Single-Ended
TIM1.AutoReloadPreload=TIM_AUTORELOAD_PRELOAD_DISABLE
TIM1.AutomaticOutput=TIM_AUTOMATICOUTPUT_DISABLE
TIM1.Break2Filter=3
TIM1.Break2Polarity=TIM_BREAK2POLARITY_HIGH
TIM1.Break2State=TIM_BREAK2_ENABLE
TIM1.BreakFilter=0
TIM1.BreakPolarity=TIM_BREAKPOLARITY_HIGH
TIM1.BreakState=TIM_BREAK_DISABLE
TIM1.Channel=TIM_CHANNEL_4
TIM1.Channel-PWM\ Generation1\ CH1\ CH1N=TIM_CHANNEL_1
TIM1.Channel-PWM\ Generation2\ CH2\ CH2N=TIM_CHANNEL_2
TIM1.Channel-PWM\ Generation3\ CH3\ CH3N=TIM_CHANNEL_3
TIM1.Channel-PWM\ Generation4\ No\ Output=TIM_CHANNEL_4
TIM1.ClearInputSource=TIM_CLEARINPUTSOURCE_NONE
TIM1.ClockDivision=TIM_CLOCKDIVISION_DIV2
TIM1.CounterMode=TIM_COUNTERMODE_CENTERALIGNED1
TIM1.DeadTime=((DEAD_TIME_COUNTS) / 2)
TIM1.LockLevel=TIM_LOCKLEVEL_1
TIM1.OCFastMode_PWM=TIM_OCFAST_DISABLE
TIM1.OCIdleState_1=TIM_OCIDLESTATE_RESET
TIM1.OCIdleState_2=TIM_OCIDLESTATE_RESET
TIM1.OCIdleState_3=TIM_OCIDLESTATE_RESET
TIM1.OCIdleState_4=TIM_OCIDLESTATE_RESET
TIM1.OCIdleState_5=TIM_OCIDLESTATE_RESET
TIM1.OCIdleState_6=TIM_OCIDLESTATE_RESET
TIM1.OCMode_PWM-PWM\ Generation1\ CH1\ CH1N=TIM_OCMODE_PWM1
TIM1.OCMode_PWM-PWM\ Generation2\ CH2\ CH2N=TIM_OCMODE_PWM1
TIM1.OCMode_PWM-PWM\ Generation3\ CH3\ CH3N=TIM_OCMODE_PWM1
TIM1.OCMode_PWM-PWM\ Generation4\ No\ Output=TIM_OCMODE_PWM2
TIM1.OCNIdleState_1=TIM_OCNIDLESTATE_RESET
TIM1.OCNIdleState_2=TIM_OCNIDLESTATE_RESET
TIM1.OCNIdleState_3=TIM_OCNIDLESTATE_RESET
TIM1.OCNPolarity_1=TIM_OCNPOLARITY_HIGH
TIM1.OCNPolarity_2=TIM_OCNPOLARITY_HIGH
TIM1.OCNPolarity_3=TIM_OCNPOLARITY_HIGH
TIM1.OCPolarity_1=TIM_OCPOLARITY_HIGH
TIM1.OCPolarity_2=TIM_OCPOLARITY_HIGH
TIM1.OCPolarity_3=TIM_OCPOLARITY_HIGH
TIM1.OCPolarity_4=TIM_OCPOLARITY_HIGH
TIM1.OCPolarity_5=TIM_OCPOLARITY_HIGH
TIM1.OCPolarity_6=TIM_OCPOLARITY_HIGH
TIM1.OffStateIDLEMode=TIM_OSSI_ENABLE
TIM1.OffStateRunMode=TIM_OSSR_ENABLE
TIM1.Period=((PWM_PERIOD_CYCLES) / 2)
TIM1.PeriodNoDither=((PWM_PERIOD_CYCLES) / 2)
TIM1.Prescaler=((TIM_CLOCK_DIVIDER) - 1)
TIM1.Pulse-PWM\ Generation1\ CH1=((PWM_PERIOD_CYCLES) / 4)
TIM1.Pulse-PWM\ Generation2\ CH2=((PWM_PERIOD_CYCLES) / 4)
TIM1.Pulse-PWM\ Generation3\ CH3=((PWM_PERIOD_CYCLES) / 4)
TIM1.Pulse-PWM\ Generation4\ No\ Output=(((PWM_PERIOD_CYCLES) / 2) - (HTMIN))
TIM1.Pulse-PWM\ Generation5\ No\ Output=(((PWM_PERIOD_CYCLES) / 2) + 1)
TIM1.Pulse-PWM\ Generation6\ No\ Output=(((PWM_PERIOD_CYCLES) / 2) + 1)
TIM1.RepetitionCounter=(REP_COUNTER)
TIM1.SourceBRK2COMP1=TIM_BREAKINPUTSOURCE_ENABLE
TIM1.SourceBRK2COMP1Polarity=TIM_BREAKINPUTSOURCE_POLARITY_HIGH
TIM1.SourceBRK2COMP2=TIM_BREAKINPUTSOURCE_ENABLE
TIM1.SourceBRK2COMP2Polarity=TIM_BREAKINPUTSOURCE_POLARITY_HIGH
TIM1.SourceBRK2COMP4=TIM_BREAKINPUTSOURCE_ENABLE
TIM1.SourceBRK2COMP4Polarity=TIM_BREAKINPUTSOURCE_POLARITY_HIGH
TIM1.SourceBRK2DigInput=TIM_BREAKINPUTSOURCE_DISABLE
TIM1.TIM_MasterOutputTrigger=TIM_TRGO_OC4REF
TIM1.TIM_MasterOutputTrigger2=TIM_TRGO2_RESET
TIM1.TIM_MasterSlaveMode=TIM_MASTERSLAVEMODE_DISABLE
TIM1.TIM_SlaveMode=TIM_SLAVEMODE_TRIGGER
TIM4.IC1Filter=M1_HALL_IC_FILTER
TIM4.Period=M1_HALL_TIM_PERIOD
USART2.BaudRate=115200
USART2.VirtualMode-Asynchronous=VM_ASYNC
USART2.WordLength=WORDLENGTH_8B
VP_ADC2_OPAMP_INTERNAL3.Mode=IN-OPAMP3
VP_COMP1_VS_VREFINT14.Mode=VREFINT_14
VP_COMP2_VS_VREFINT14.Mode=VREFINT_14
VP_COMP4_VS_VREFINT14.Mode=VREFINT_14
VP_CORDIC_VS_CORDIC.Mode=CORDIC_Activate
VP_MotorControl_MC_ENABLED.Mode=Enabled
VP_SYS_VS_DBSignals.Mode=DisableDeadBatterySignals
VP_TIM1_VS_ClockSourceITR.Mode=TriggerSource_ITR1
VP_TIM1_VS_ControllerModeTrigger.Mode=Trigger Mode
VP_TIM1_VS_no_output4.Mode=PWM Generation4 No Output
VP_TIM4_VS_ClockSourceINT.Mode=Internal
board=custom

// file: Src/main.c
/* USER CODE BEGIN Header */
/**
  ******************************************************************************
  * @file           : main.c
  * @brief          : Main program body
  ******************************************************************************
  * @attention
  *
  * <h2><center>&copy; Copyright (c) 2021 STMicroelectronics.
  * All rights reserved.</center></h2>
  *
  * This software component is licensed by ST under Ultimate Liberty license
  * SLA0044, the "License"; You may not use this file except in compliance with
  * the License. You may obtain a copy of the License at:
  *                             www.st.com/SLA0044
  *
  ******************************************************************************
  */
/* USER CODE END Header */

#include "main.h"
#include "motorcontrol.h"
#include "drive_Parameters.h"
/* USER CODE BEGIN Includes */
#include "string.h"
/* USER CODE END Includes */

/* USER CODE BEGIN PD */
extern MCI_Handle_t* pMCI[NBR_OF_MOTORS];
/* USER CODE END PD */

ADC_HandleTypeDef hadc1;
ADC_HandleTypeDef hadc2;

COMP_HandleTypeDef hcomp1;
COMP_HandleTypeDef hcomp2;
COMP_HandleTypeDef hcomp4;

CORDIC_HandleTypeDef hcordic;

DAC_HandleTypeDef hdac1;

FDCAN_HandleTypeDef hfdcan1;

OPAMP_HandleTypeDef hopamp1;
OPAMP_HandleTypeDef hopamp2;
OPAMP_HandleTypeDef hopamp3;

TIM_HandleTypeDef htim1;
TIM_HandleTypeDef htim4;

UART_HandleTypeDef huart2;

/* USER CODE BEGIN PV */
uint8_t status=0;
extern PID_Handle_t PIDSpeedHandle_M1;
extern PID_Handle_t PIDIqHandle_M1;
extern PID_Handle_t PIDIdHandle_M1;
/* USER CODE END PV */

void SystemClock_Config(void);
static void MX_GPIO_Init(void);
static void MX_ADC1_Init(void);
static void MX_ADC2_Init(void);
static void MX_COMP1_Init(void);
static void MX_COMP2_Init(void);
static void MX_COMP4_Init(void);
static void MX_CORDIC_Init(void);
static void MX_DAC1_Init(void);
static void MX_FDCAN1_Init(void);
static void MX_OPAMP1_Init(void);
static void MX_OPAMP2_Init(void);
static void MX_OPAMP3_Init(void);
static void MX_TIM1_Init(void);
static void MX_TIM4_Init(void);
static void MX_USART2_UART_Init(void);
static void MX_NVIC_Init(void);

/* USER CODE BEGIN 0 */
#define CAN_ID 0x201

void HAL_FDCAN_RxFifo0Callback(FDCAN_HandleTypeDef *hfdcan, uint32_t RxFifo0ITs)
{
	FDCAN_RxHeaderTypeDef RxHeader;
	uint8_t msgData[8];
	int16_t newSpeed;
	int16_t newTorque;
	HAL_FDCAN_GetRxMessage(hfdcan,FDCAN_RX_FIFO0,&RxHeader,msgData);
	if(RxHeader.Identifier==CAN_ID)
	{
		switch (msgData[0])
		{
		case 0x01:
			MCI_ExecSpeedRamp(pMCI[0],0,1);
			MCI_StartMotor(pMCI[0]);
			status=1;
			break;
		case 0x02:
			MCI_StopMotor(pMCI[0]);
			MCI_ExecSpeedRamp(pMCI[0],0,1);
			status=0;
			break;
		case 0x03:
			newSpeed=msgData[1]+(msgData[2]<<8);
			MCI_ExecSpeedRamp(pMCI[0],newSpeed/6,1);
			break;
		case 0x04:
			PIDSpeedHandle_M1.hKpGain=msgData[1]+(msgData[2]<<8);
			PIDSpeedHandle_M1.hKiGain=msgData[3]+(msgData[4]<<8);
			PIDSpeedHandle_M1.hKdGain=msgData[5]+(msgData[6]<<8);
			break;
		case 0x05:
			PIDIqHandle_M1.hKpGain=msgData[1]+(msgData[2]<<8);
			PIDIqHandle_M1.hKiGain=msgData[3]+(msgData[4]<<8);
			PIDIqHandle_M1.hKdGain=msgData[5]+(msgData[6]<<8);
			break;
		case 0x06:
			PIDIdHandle_M1.hKpGain=msgData[1]+(msgData[2]<<8);
			PIDIdHandle_M1.hKiGain=msgData[3]+(msgData[4]<<8);
			PIDIdHandle_M1.hKdGain=msgData[5]+(msgData[6]<<8);
			break;
		case 0x07:
			newTorque=msgData[1]+(msgData[2]<<8);
			MCI_ExecTorqueRamp(pMCI[0],newTorque/6,1);
			break;
		}
	}
}

/* USER CODE END 0 */

int main(void)
{

  /* MCU Configuration--------------------------------------------------------*/

  /* Reset of all peripherals, Initializes the Flash interface and the Systick. */
  HAL_Init();

  /* Configure the system clock */
  SystemClock_Config();

  /* Initialize all configured peripherals */
  MX_GPIO_Init();
  MX_ADC1_Init();
  MX_ADC2_Init();
  MX_COMP1_Init();
  MX_COMP2_Init();
  MX_COMP4_Init();
  MX_CORDIC_Init();
  MX_DAC1_Init();
  MX_FDCAN1_Init();
  MX_OPAMP1_Init();
  MX_OPAMP2_Init();
  MX_OPAMP3_Init();
  MX_TIM1_Init();
  MX_TIM4_Init();
  MX_USART2_UART_Init();
  MX_MotorControl_Init();

  /* Initialize interrupts */
  MX_NVIC_Init();
  /* USER CODE BEGIN 2 */
  FDCAN_FilterTypeDef fdcanFilter;
  fdcanFilter.FilterConfig=FDCAN_FILTER_TO_RXFIFO0;
  fdcanFilter.FilterID1=0;
  fdcanFilter.FilterID2=0xFFFF;
  fdcanFilter.FilterIndex=0x321;
  fdcanFilter.FilterType=FDCAN_FILTER_DUAL;
  fdcanFilter.IdType=FDCAN_STANDARD_ID;
  HAL_FDCAN_ConfigFilter(&hfdcan1,&fdcanFilter);
  HAL_FDCAN_Start(&hfdcan1);
  HAL_FDCAN_ActivateNotification(&hfdcan1,FDCAN_IT_RX_FIFO0_NEW_MESSAGE,0);

  MCI_StartMotor(pMCI[0]);
  HAL_Delay(100);
  MCI_StopMotor(pMCI[0]);
  /* USER CODE END 2 */

  /* Infinite loop */
  while (1)
  {
	MCI_FaultAcknowledged(pMCI[0]);
	if(status)
	{
		MCI_StartMotor(pMCI[0]);
	}
	HAL_Delay(10);
  }
}

void SystemClock_Config(void)
{
  RCC_OscInitTypeDef RCC_OscInitStruct = {0};
  RCC_ClkInitTypeDef RCC_ClkInitStruct = {0};
  RCC_PeriphCLKInitTypeDef PeriphClkInit = {0};

  /** Configure the main internal regulator output voltage
  */
  HAL_PWREx_ControlVoltageScaling(PWR_REGULATOR_VOLTAGE_SCALE1_BOOST);
  /** Initializes the CPU, AHB and APB busses clocks
  */
  RCC_OscInitStruct.OscillatorType = RCC_OSCILLATORTYPE_HSE;
  RCC_OscInitStruct.HSEState = RCC_HSE_ON;
  RCC_OscInitStruct.PLL.PLLState = RCC_PLL_ON;
  RCC_OscInitStruct.PLL.PLLSource = RCC_PLLSOURCE_HSE;
  RCC_OscInitStruct.PLL.PLLM = RCC_PLLM_DIV2;
  RCC_OscInitStruct.PLL.PLLN = 85;
  RCC_OscInitStruct.PLL.PLLP = RCC_PLLP_DIV8;
  RCC_OscInitStruct.PLL.PLLQ = RCC_PLLQ_DIV2;
  RCC_OscInitStruct.PLL.PLLR = RCC_PLLR_DIV2;
  if (HAL_RCC_OscConfig(&RCC_OscInitStruct) != HAL_OK)
  {
    Error_Handler();
  }
  /** Initializes the CPU, AHB and APB busses clocks
  */
  RCC_ClkInitStruct.ClockType = RCC_CLOCKTYPE_HCLK|RCC_CLOCKTYPE_SYSCLK
                              |RCC_CLOCKTYPE_PCLK1|RCC_CLOCKTYPE_PCLK2;
  RCC_ClkInitStruct.SYSCLKSource = RCC_SYSCLKSOURCE_PLLCLK;
  RCC_ClkInitStruct.AHBCLKDivider = RCC_SYSCLK_DIV1;
  RCC_ClkInitStruct.APB1CLKDivider = RCC_HCLK_DIV1;
  RCC_ClkInitStruct.APB2CLKDivider = RCC_HCLK_DIV1;

  if (HAL_RCC_ClockConfig(&RCC_ClkInitStruct, FLASH_LATENCY_8) != HAL_OK)
  {
    Error_Handler();
  }
  /** Initializes the peripherals clocks
  */
  PeriphClkInit.PeriphClockSelection = RCC_PERIPHCLK_USART2|RCC_PERIPHCLK_ADC12
                              |RCC_PERIPHCLK_FDCAN;
  PeriphClkInit.Usart2ClockSelection = RCC_USART2CLKSOURCE_PCLK1;
  PeriphClkInit.FdcanClockSelection = RCC_FDCANCLKSOURCE_PCLK1;
  PeriphClkInit.Adc12ClockSelection = RCC_ADC12CLKSOURCE_PLL;
  if (HAL_RCCEx_PeriphCLKConfig(&PeriphClkInit) != HAL_OK)
  {
    Error_Handler();
  }
}

/**
  * @brief NVIC Configuration.
  * @retval None
  */
static void MX_NVIC_Init(void)
{
  /* TIM1_BRK_TIM15_IRQn interrupt configuration */
  HAL_NVIC_SetPriority(TIM1_BRK_TIM15_IRQn, 4, 1);
  HAL_NVIC_EnableIRQ(TIM1_BRK_TIM15_IRQn);
  /* TIM1_UP_TIM16_IRQn interrupt configuration */
  HAL_NVIC_SetPriority(TIM1_UP_TIM16_IRQn, 0, 0);
  HAL_NVIC_EnableIRQ(TIM1_UP_TIM16_IRQn);
  /* ADC1_2_IRQn interrupt configuration */
  HAL_NVIC_SetPriority(ADC1_2_IRQn, 2, 0);
  HAL_NVIC_EnableIRQ(ADC1_2_IRQn);
  /* TIM4_IRQn interrupt configuration */
  HAL_NVIC_SetPriority(TIM4_IRQn, 3, 0);
  HAL_NVIC_EnableIRQ(TIM4_IRQn);
  /* USART2_IRQn interrupt configuration */
  HAL_NVIC_SetPriority(USART2_IRQn, 3, 1);
  HAL_NVIC_EnableIRQ(USART2_IRQn);
  /* EXTI15_10_IRQn interrupt configuration */
  HAL_NVIC_SetPriority(EXTI15_10_IRQn, 3, 0);
  HAL_NVIC_EnableIRQ(EXTI15_10_IRQn);
}

static void MX_ADC1_Init(void)
{

  ADC_MultiModeTypeDef multimode = {0};
  ADC_InjectionConfTypeDef sConfigInjected = {0};
  ADC_ChannelConfTypeDef sConfig = {0};

  /** Common config
  */
  hadc1.Instance = ADC1;
  hadc1.Init.ClockPrescaler = ADC_CLOCK_ASYNC_DIV4;
  hadc1.Init.Resolution = ADC_RESOLUTION_12B;
  hadc1.Init.DataAlign = ADC_DATAALIGN_LEFT;
  hadc1.Init.GainCompensation = 0;
  hadc1.Init.ScanConvMode = ADC_SCAN_ENABLE;
  hadc1.Init.EOCSelection = ADC_EOC_SINGLE_CONV;
  hadc1.Init.LowPowerAutoWait = DISABLE;
  hadc1.Init.ContinuousConvMode = DISABLE;
  hadc1.Init.NbrOfConversion = 2;
  hadc1.Init.DiscontinuousConvMode = DISABLE;
  hadc1.Init.ExternalTrigConv = ADC_SOFTWARE_START;
  hadc1.Init.ExternalTrigConvEdge = ADC_EXTERNALTRIGCONVEDGE_NONE;
  hadc1.Init.DMAContinuousRequests = DISABLE;
  hadc1.Init.Overrun = ADC_OVR_DATA_PRESERVED;
  hadc1.Init.OversamplingMode = DISABLE;
  if (HAL_ADC_Init(&hadc1) != HAL_OK)
  {
    Error_Handler();
  }
  /** Configure the ADC multi-mode
  */
  multimode.Mode = ADC_MODE_INDEPENDENT;
  if (HAL_ADCEx_MultiModeConfigChannel(&hadc1, &multimode) != HAL_OK)
  {
    Error_Handler();
  }
  /** Configure Injected Channel
  */
  sConfigInjected.InjectedChannel = ADC_CHANNEL_3;
  sConfigInjected.InjectedRank = ADC_INJECTED_RANK_1;
  sConfigInjected.InjectedSamplingTime = ADC_SAMPLETIME_6CYCLES_5;
  sConfigInjected.InjectedSingleDiff = ADC_SINGLE_ENDED;
  sConfigInjected.InjectedOffsetNumber = ADC_OFFSET_NONE;
  sConfigInjected.InjectedOffset = 0;
  sConfigInjected.InjectedNbrOfConversion = 2;
  sConfigInjected.InjectedDiscontinuousConvMode = DISABLE;
  sConfigInjected.AutoInjectedConv = DISABLE;
  sConfigInjected.QueueInjectedContext = DISABLE;
  sConfigInjected.ExternalTrigInjecConv = ADC_EXTERNALTRIGINJEC_T1_CC4;
  sConfigInjected.ExternalTrigInjecConvEdge = ADC_EXTERNALTRIGINJECCONV_EDGE_RISING;
  sConfigInjected.InjecOversamplingMode = DISABLE;
  if (HAL_ADCEx_InjectedConfigChannel(&hadc1, &sConfigInjected) != HAL_OK)
  {
    Error_Handler();
  }
  /** Configure Injected Channel
  */
  sConfigInjected.InjectedChannel = ADC_CHANNEL_12;
  sConfigInjected.InjectedRank = ADC_INJECTED_RANK_2;
  if (HAL_ADCEx_InjectedConfigChannel(&hadc1, &sConfigInjected) != HAL_OK)
  {
    Error_Handler();
  }
  /** Configure Regular Channel
  */
  sConfig.Channel = ADC_CHANNEL_1;
  sConfig.Rank = ADC_REGULAR_RANK_1;
  sConfig.SamplingTime = ADC_SAMPLETIME_47CYCLES_5;
  sConfig.SingleDiff = ADC_SINGLE_ENDED;
  sConfig.OffsetNumber = ADC_OFFSET_NONE;
  sConfig.Offset = 0;
  if (HAL_ADC_ConfigChannel(&hadc1, &sConfig) != HAL_OK)
  {
    Error_Handler();
  }
  /** Configure Regular Channel
  */
  sConfig.Channel = ADC_CHANNEL_5;
  sConfig.Rank = ADC_REGULAR_RANK_2;
  if (HAL_ADC_ConfigChannel(&hadc1, &sConfig) != HAL_OK)
  {
    Error_Handler();
  }

}

static void MX_ADC2_Init(void)
{

  ADC_InjectionConfTypeDef sConfigInjected = {0};

  /** Common config
  */
  hadc2.Instance = ADC2;
  hadc2.Init.ClockPrescaler = ADC_CLOCK_ASYNC_DIV4;
  hadc2.Init.Resolution = ADC_RESOLUTION_12B;
  hadc2.Init.DataAlign = ADC_DATAALIGN_LEFT;
  hadc2.Init.GainCompensation = 0;
  hadc2.Init.ScanConvMode = ADC_SCAN_ENABLE;
  hadc2.Init.EOCSelection = ADC_EOC_SINGLE_CONV;
  hadc2.Init.LowPowerAutoWait = DISABLE;
  hadc2.Init.ContinuousConvMode = DISABLE;
  hadc2.Init.NbrOfConversion = 1;
  hadc2.Init.DiscontinuousConvMode = DISABLE;
  hadc2.Init.DMAContinuousRequests = DISABLE;
  hadc2.Init.Overrun = ADC_OVR_DATA_PRESERVED;
  hadc2.Init.OversamplingMode = DISABLE;
  if (HAL_ADC_Init(&hadc2) != HAL_OK)
  {
    Error_Handler();
  }
  /** Configure Injected Channel
  */
  sConfigInjected.InjectedChannel = ADC_CHANNEL_3;
  sConfigInjected.InjectedRank = ADC_INJECTED_RANK_1;
  sConfigInjected.InjectedSamplingTime = ADC_SAMPLETIME_6CYCLES_5;
  sConfigInjected.InjectedSingleDiff = ADC_SINGLE_ENDED;
  sConfigInjected.InjectedOffsetNumber = ADC_OFFSET_NONE;
  sConfigInjected.InjectedOffset = 0;
  sConfigInjected.InjectedNbrOfConversion = 2;
  sConfigInjected.InjectedDiscontinuousConvMode = DISABLE;
  sConfigInjected.AutoInjectedConv = DISABLE;
  sConfigInjected.QueueInjectedContext = DISABLE;
  sConfigInjected.ExternalTrigInjecConv = ADC_EXTERNALTRIGINJEC_T1_CC4;
  sConfigInjected.ExternalTrigInjecConvEdge = ADC_EXTERNALTRIGINJECCONV_EDGE_RISING;
  sConfigInjected.InjecOversamplingMode = DISABLE;
  if (HAL_ADCEx_InjectedConfigChannel(&hadc2, &sConfigInjected) != HAL_OK)
  {
    Error_Handler();
  }
  /** Configure Injected Channel
  */
  sConfigInjected.InjectedChannel = ADC_CHANNEL_VOPAMP3_ADC2;
  sConfigInjected.InjectedRank = ADC_INJECTED_RANK_2;
  if (HAL_ADCEx_InjectedConfigChannel(&hadc2, &sConfigInjected) != HAL_OK)
  {
    Error_Handler();
  }

}

static void MX_COMP1_Init(void)
{

  hcomp1.Instance = COMP1;
  hcomp1.Init.InputPlus = COMP_INPUT_PLUS_IO1;
  hcomp1.Init.InputMinus = COMP_INPUT_MINUS_1_4VREFINT;
  hcomp1.Init.OutputPol = COMP_OUTPUTPOL_NONINVERTED;
  hcomp1.Init.Hysteresis = COMP_HYSTERESIS_NONE;
  hcomp1.Init.BlankingSrce = COMP_BLANKINGSRC_NONE;
  hcomp1.Init.TriggerMode = COMP_TRIGGERMODE_NONE;
  if (HAL_COMP_Init(&hcomp1) != HAL_OK)
  {
    Error_Handler();
  }

}

static void MX_COMP2_Init(void)
{

  hcomp2.Instance = COMP2;
  hcomp2.Init.InputPlus = COMP_INPUT_PLUS_IO1;
  hcomp2.Init.InputMinus = COMP_INPUT_MINUS_1_4VREFINT;
  hcomp2.Init.OutputPol = COMP_OUTPUTPOL_NONINVERTED;
  hcomp2.Init.Hysteresis = COMP_HYSTERESIS_NONE;
  hcomp2.Init.BlankingSrce = COMP_BLANKINGSRC_NONE;
  hcomp2.Init.TriggerMode = COMP_TRIGGERMODE_NONE;
  if (HAL_COMP_Init(&hcomp2) != HAL_OK)
  {
    Error_Handler();
  }

}

static void MX_COMP4_Init(void)
{

  hcomp4.Instance = COMP4;
  hcomp4.Init.InputPlus = COMP_INPUT_PLUS_IO1;
  hcomp4.Init.InputMinus = COMP_INPUT_MINUS_1_4VREFINT;
  hcomp4.Init.OutputPol = COMP_OUTPUTPOL_NONINVERTED;
  hcomp4.Init.Hysteresis = COMP_HYSTERESIS_NONE;
  hcomp4.Init.BlankingSrce = COMP_BLANKINGSRC_NONE;
  hcomp4.Init.TriggerMode = COMP_TRIGGERMODE_NONE;
  if (HAL_COMP_Init(&hcomp4) != HAL_OK)
  {
    Error_Handler();
  }

}

static void MX_CORDIC_Init(void)
{

  hcordic.Instance = CORDIC;
  if (HAL_CORDIC_Init(&hcordic) != HAL_OK)
  {
    Error_Handler();
  }

}

static void MX_DAC1_Init(void)
{

  DAC_ChannelConfTypeDef sConfig = {0};

  /** DAC Initialization
  */
  hdac1.Instance = DAC1;
  if (HAL_DAC_Init(&hdac1) != HAL_OK)
  {
    Error_Handler();
  }
  /** DAC channel OUT1 config
  */
  sConfig.DAC_HighFrequency = DAC_HIGH_FREQUENCY_INTERFACE_MODE_AUTOMATIC;
  sConfig.DAC_DMADoubleDataMode = DISABLE;
  sConfig.DAC_SignedFormat = DISABLE;
  sConfig.DAC_SampleAndHold = DAC_SAMPLEANDHOLD_DISABLE;
  sConfig.DAC_Trigger = DAC_TRIGGER_SOFTWARE;
  sConfig.DAC_Trigger2 = DAC_TRIGGER_NONE;
  sConfig.DAC_OutputBuffer = DAC_OUTPUTBUFFER_DISABLE;
  sConfig.DAC_ConnectOnChipPeripheral = DAC_CHIPCONNECT_DISABLE;
  sConfig.DAC_UserTrimming = DAC_TRIMMING_FACTORY;
  if (HAL_DAC_ConfigChannel(&hdac1, &sConfig, DAC_CHANNEL_1) != HAL_OK)
  {
    Error_Handler();
  }

}

static void MX_FDCAN1_Init(void)
{

  hfdcan1.Instance = FDCAN1;
  hfdcan1.Init.ClockDivider = FDCAN_CLOCK_DIV10;
  hfdcan1.Init.FrameFormat = FDCAN_FRAME_CLASSIC;
  hfdcan1.Init.Mode = FDCAN_MODE_NORMAL;
  hfdcan1.Init.AutoRetransmission = DISABLE;
  hfdcan1.Init.TransmitPause = DISABLE;
  hfdcan1.Init.ProtocolException = DISABLE;
  hfdcan1.Init.NominalPrescaler = 2;
  hfdcan1.Init.NominalSyncJumpWidth = 2;
  hfdcan1.Init.NominalTimeSeg1 = 14;
  hfdcan1.Init.NominalTimeSeg2 = 2;
  hfdcan1.Init.DataPrescaler = 2;
  hfdcan1.Init.DataSyncJumpWidth = 2;
  hfdcan1.Init.DataTimeSeg1 = 14;
  hfdcan1.Init.DataTimeSeg2 = 2;
  hfdcan1.Init.StdFiltersNbr = 0;
  hfdcan1.Init.ExtFiltersNbr = 0;
  hfdcan1.Init.TxFifoQueueMode = FDCAN_TX_FIFO_OPERATION;
  if (HAL_FDCAN_Init(&hfdcan1) != HAL_OK)
  {
    Error_Handler();
  }

}

static void MX_OPAMP1_Init(void)
{

  hopamp1.Instance = OPAMP1;
  hopamp1.Init.PowerMode = OPAMP_POWERMODE_NORMAL;
  hopamp1.Init.Mode = OPAMP_PGA_MODE;
  hopamp1.Init.NonInvertingInput = OPAMP_NONINVERTINGINPUT_IO0;
  hopamp1.Init.InternalOutput = DISABLE;
  hopamp1.Init.TimerControlledMuxmode = OPAMP_TIMERCONTROLLEDMUXMODE_DISABLE;
  hopamp1.Init.PgaConnect = OPAMP_PGA_CONNECT_INVERTINGINPUT_IO0_BIAS;
  hopamp1.Init.PgaGain = OPAMP_PGA_GAIN_16_OR_MINUS_15;
  hopamp1.Init.UserTrimming = OPAMP_TRIMMING_FACTORY;
  if (HAL_OPAMP_Init(&hopamp1) != HAL_OK)
  {
    Error_Handler();
  }

}

static void MX_OPAMP2_Init(void)
{

  hopamp2.Instance = OPAMP2;
  hopamp2.Init.PowerMode = OPAMP_POWERMODE_NORMAL;
  hopamp2.Init.Mode = OPAMP_PGA_MODE;
  hopamp2.Init.NonInvertingInput = OPAMP_NONINVERTINGINPUT_IO0;
  hopamp2.Init.InternalOutput = DISABLE;
  hopamp2.Init.TimerControlledMuxmode = OPAMP_TIMERCONTROLLEDMUXMODE_DISABLE;
  hopamp2.Init.PgaConnect = OPAMP_PGA_CONNECT_INVERTINGINPUT_IO0_BIAS;
  hopamp2.Init.PgaGain = OPAMP_PGA_GAIN_16_OR_MINUS_15;
  hopamp2.Init.UserTrimming = OPAMP_TRIMMING_FACTORY;
  if (HAL_OPAMP_Init(&hopamp2) != HAL_OK)
  {
    Error_Handler();
  }

}

static void MX_OPAMP3_Init(void)
{

  hopamp3.Instance = OPAMP3;
  hopamp3.Init.PowerMode = OPAMP_POWERMODE_NORMAL;
  hopamp3.Init.Mode = OPAMP_PGA_MODE;
  hopamp3.Init.NonInvertingInput = OPAMP_NONINVERTINGINPUT_IO0;
  hopamp3.Init.InternalOutput = ENABLE;
  hopamp3.Init.TimerControlledMuxmode = OPAMP_TIMERCONTROLLEDMUXMODE_DISABLE;
  hopamp3.Init.PgaConnect = OPAMP_PGA_CONNECT_INVERTINGINPUT_IO0_BIAS;
  hopamp3.Init.PgaGain = OPAMP_PGA_GAIN_16_OR_MINUS_15;
  hopamp3.Init.UserTrimming = OPAMP_TRIMMING_FACTORY;
  if (HAL_OPAMP_Init(&hopamp3) != HAL_OK)
  {
    Error_Handler();
  }

}

static void MX_TIM1_Init(void)
{

  TIM_SlaveConfigTypeDef sSlaveConfig = {0};
  TIM_MasterConfigTypeDef sMasterConfig = {0};
  TIMEx_BreakInputConfigTypeDef sBreakInputConfig = {0};
  TIM_OC_InitTypeDef sConfigOC = {0};
  TIM_BreakDeadTimeConfigTypeDef sBreakDeadTimeConfig = {0};

  htim1.Instance = TIM1;
  htim1.Init.Prescaler = ((TIM_CLOCK_DIVIDER) - 1);
  htim1.Init.CounterMode = TIM_COUNTERMODE_CENTERALIGNED1;
  htim1.Init.Period = ((PWM_PERIOD_CYCLES) / 2);
  htim1.Init.ClockDivision = TIM_CLOCKDIVISION_DIV2;
  htim1.Init.RepetitionCounter = (REP_COUNTER);
  htim1.Init.AutoReloadPreload = TIM_AUTORELOAD_PRELOAD_DISABLE;
  if (HAL_TIM_Base_Init(&htim1) != HAL_OK)
  {
    Error_Handler();
  }
  if (HAL_TIM_PWM_Init(&htim1) != HAL_OK)
  {
    Error_Handler();
  }
  sSlaveConfig.SlaveMode = TIM_SLAVEMODE_TRIGGER;
  sSlaveConfig.InputTrigger = TIM_TS_ITR1;
  if (HAL_TIM_SlaveConfigSynchro(&htim1, &sSlaveConfig) != HAL_OK)
  {
    Error_Handler();
  }
  sMasterConfig.MasterOutputTrigger = TIM_TRGO_OC4REF;
  sMasterConfig.MasterOutputTrigger2 = TIM_TRGO2_RESET;
  sMasterConfig.MasterSlaveMode = TIM_MASTERSLAVEMODE_DISABLE;
  if (HAL_TIMEx_MasterConfigSynchronization(&htim1, &sMasterConfig) != HAL_OK)
  {
    Error_Handler();
  }
  sBreakInputConfig.Source = TIM_BREAKINPUTSOURCE_COMP1;
  sBreakInputConfig.Enable = TIM_BREAKINPUTSOURCE_ENABLE;
  sBreakInputConfig.Polarity = TIM_BREAKINPUTSOURCE_POLARITY_HIGH;
  if (HAL_TIMEx_ConfigBreakInput(&htim1, TIM_BREAKINPUT_BRK2, &sBreakInputConfig) != HAL_OK)
  {
    Error_Handler();
  }
  sBreakInputConfig.Source = TIM_BREAKINPUTSOURCE_COMP2;
  if (HAL_TIMEx_ConfigBreakInput(&htim1, TIM_BREAKINPUT_BRK2, &sBreakInputConfig) != HAL_OK)
  {
    Error_Handler();
  }
  sBreakInputConfig.Source = TIM_BREAKINPUTSOURCE_COMP4;
  if (HAL_TIMEx_ConfigBreakInput(&htim1, TIM_BREAKINPUT_BRK2, &sBreakInputConfig) != HAL_OK)
  {
    Error_Handler();
  }
  sConfigOC.OCMode = TIM_OCMODE_PWM1;
  sConfigOC.Pulse = 0;
  sConfigOC.OCPolarity = TIM_OCPOLARITY_HIGH;
  sConfigOC.OCNPolarity = TIM_OCNPOLARITY_HIGH;
  sConfigOC.OCFastMode = TIM_OCFAST_DISABLE;
  sConfigOC.OCIdleState = TIM_OCIDLESTATE_RESET;
  sConfigOC.OCNIdleState = TIM_OCNIDLESTATE_RESET;
  if (HAL_TIM_PWM_ConfigChannel(&htim1, &sConfigOC, TIM_CHANNEL_1) != HAL_OK)
  {
    Error_Handler();
  }
  sConfigOC.Pulse = 0;
  if (HAL_TIM_PWM_ConfigChannel(&htim1, &sConfigOC, TIM_CHANNEL_2) != HAL_OK)
  {
    Error_Handler();
  }
  sConfigOC.Pulse = 0;
  if (HAL_TIM_PWM_ConfigChannel(&htim1, &sConfigOC, TIM_CHANNEL_3) != HAL_OK)
  {
    Error_Handler();
  }
  sConfigOC.OCMode = TIM_OCMODE_PWM2;
  sConfigOC.Pulse = 0;
  sConfigOC.OCNPolarity = TIM_OCNPOLARITY_HIGH;
  if (HAL_TIM_PWM_ConfigChannel(&htim1, &sConfigOC, TIM_CHANNEL_4) != HAL_OK)
  {
    Error_Handler();
  }
  sBreakDeadTimeConfig.OffStateRunMode = TIM_OSSR_ENABLE;
  sBreakDeadTimeConfig.OffStateIDLEMode = TIM_OSSI_ENABLE;
  sBreakDeadTimeConfig.LockLevel = TIM_LOCKLEVEL_1;
  sBreakDeadTimeConfig.DeadTime = ((DEAD_TIME_COUNTS) / 2);
  sBreakDeadTimeConfig.BreakState = TIM_BREAK_DISABLE;
  sBreakDeadTimeConfig.BreakPolarity = TIM_BREAKPOLARITY_HIGH;
  sBreakDeadTimeConfig.BreakFilter = 0;
  sBreakDeadTimeConfig.BreakAFMode = TIM_BREAK_AFMODE_INPUT;
  sBreakDeadTimeConfig.Break2State = TIM_BREAK2_ENABLE;
  sBreakDeadTimeConfig.Break2Polarity = TIM_BREAK2POLARITY_HIGH;
  sBreakDeadTimeConfig.Break2Filter = 3;
  sBreakDeadTimeConfig.Break2AFMode = TIM_BREAK_AFMODE_INPUT;
  sBreakDeadTimeConfig.AutomaticOutput = TIM_AUTOMATICOUTPUT_DISABLE;
  if (HAL_TIMEx_ConfigBreakDeadTime(&htim1, &sBreakDeadTimeConfig) != HAL_OK)
  {
    Error_Handler();
  }
  HAL_TIM_MspPostInit(&htim1);

}

static void MX_TIM4_Init(void)
{

  TIM_ClockConfigTypeDef sClockSourceConfig = {0};
  TIM_HallSensor_InitTypeDef sConfig = {0};
  TIM_MasterConfigTypeDef sMasterConfig = {0};

  htim4.Instance = TIM4;
  htim4.Init.Prescaler = 0;
  htim4.Init.CounterMode = TIM_COUNTERMODE_UP;
  htim4.Init.Period = M1_HALL_TIM_PERIOD;
  htim4.Init.ClockDivision = TIM_CLOCKDIVISION_DIV1;
  htim4.Init.AutoReloadPreload = TIM_AUTORELOAD_PRELOAD_DISABLE;
  if (HAL_TIM_Base_Init(&htim4) != HAL_OK)
  {
    Error_Handler();
  }
  sClockSourceConfig.ClockSource = TIM_CLOCKSOURCE_INTERNAL;
  if (HAL_TIM_ConfigClockSource(&htim4, &sClockSourceConfig) != HAL_OK)
  {
    Error_Handler();
  }
  sConfig.IC1Polarity = TIM_ICPOLARITY_RISING;
  sConfig.IC1Prescaler = TIM_ICPSC_DIV1;
  sConfig.IC1Filter = M1_HALL_IC_FILTER;
  sConfig.Commutation_Delay = 0;
  if (HAL_TIMEx_HallSensor_Init(&htim4, &sConfig) != HAL_OK)
  {
    Error_Handler();
  }
  sMasterConfig.MasterOutputTrigger = TIM_TRGO_OC2REF;
  sMasterConfig.MasterSlaveMode = TIM_MASTERSLAVEMODE_DISABLE;
  if (HAL_TIMEx_MasterConfigSynchronization(&htim4, &sMasterConfig) != HAL_OK)
  {
    Error_Handler();
  }

}

static void MX_USART2_UART_Init(void)
{

  huart2.Instance = USART2;
  huart2.Init.BaudRate = 115200;
  huart2.Init.WordLength = UART_WORDLENGTH_8B;
  huart2.Init.StopBits = UART_STOPBITS_1;
  huart2.Init.Parity = UART_PARITY_NONE;
  huart2.Init.Mode = UART_MODE_TX_RX;
  huart2.Init.HwFlowCtl = UART_HWCONTROL_NONE;
  huart2.Init.OverSampling = UART_OVERSAMPLING_16;
  huart2.Init.OneBitSampling = UART_ONE_BIT_SAMPLE_DISABLE;
  huart2.Init.ClockPrescaler = UART_PRESCALER_DIV1;
  huart2.AdvancedInit.AdvFeatureInit = UART_ADVFEATURE_NO_INIT;
  if (HAL_UART_Init(&huart2) != HAL_OK)
  {
    Error_Handler();
  }
  if (HAL_UARTEx_SetTxFifoThreshold(&huart2, UART_TXFIFO_THRESHOLD_1_8) != HAL_OK)
  {
    Error_Handler();
  }
  if (HAL_UARTEx_SetRxFifoThreshold(&huart2, UART_RXFIFO_THRESHOLD_1_8) != HAL_OK)
  {
    Error_Handler();
  }
  if (HAL_UARTEx_DisableFifoMode(&huart2) != HAL_OK)
  {
    Error_Handler();
  }

}

static void MX_GPIO_Init(void)
{
  GPIO_InitTypeDef GPIO_InitStruct = {0};

  /* GPIO Ports Clock Enable */
  __HAL_RCC_GPIOC_CLK_ENABLE();
  __HAL_RCC_GPIOF_CLK_ENABLE();
  __HAL_RCC_GPIOA_CLK_ENABLE();
  __HAL_RCC_GPIOB_CLK_ENABLE();

  /*Configure GPIO pin : Start_Stop_Pin */
  GPIO_InitStruct.Pin = Start_Stop_Pin;
  GPIO_InitStruct.Mode = GPIO_MODE_IT_FALLING;
  GPIO_InitStruct.Pull = GPIO_NOPULL;
  HAL_GPIO_Init(Start_Stop_GPIO_Port, &GPIO_InitStruct);

}

void Error_Handler(void)
{
}

/************************ (C) COPYRIGHT STMicroelectronics *****END OF FILE****/
